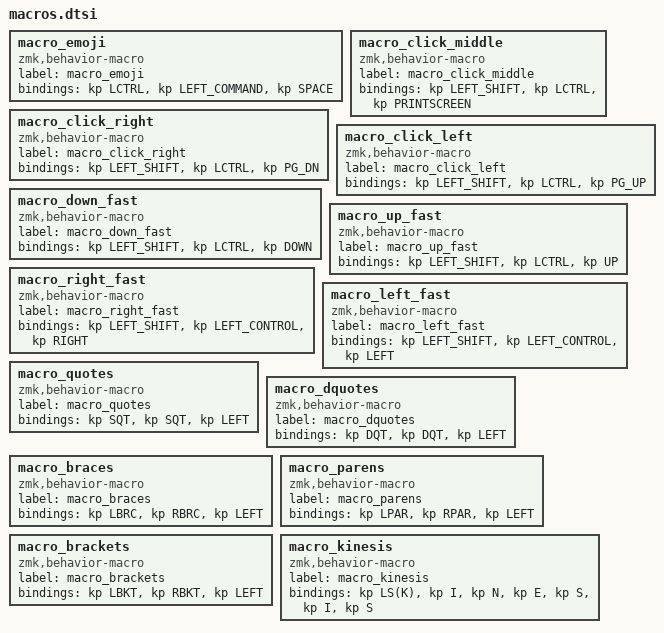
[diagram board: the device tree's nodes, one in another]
macro_emoji: macro_emoji{
compatible = "zmk,behavior-macro";
label = "macro_emoji";
#binding-cells = <0>;
bindings = <&kp LCTRL>, <&kp LEFT_COMMAND>, <&kp SPACE>;
};
macro_click_middle: macro_click_middle{
compatible = "zmk,behavior-macro";
label = "macro_click_middle";
#binding-cells = <0>;
bindings = <&kp LEFT_SHIFT>, <&kp LCTRL>, <&kp PRINTSCREEN>;
};
macro_click_right: macro_click_right{
compatible = "zmk,behavior-macro";
label = "macro_click_right";
#binding-cells = <0>;
bindings = <&kp LEFT_SHIFT>, <&kp LCTRL>, <&kp PG_DN>;
};
macro_click_left: macro_click_left{
compatible = "zmk,behavior-macro";
label = "macro_click_left";
#binding-cells = <0>;
bindings = <&kp LEFT_SHIFT>, <&kp LCTRL>, <&kp PG_UP>;
};
macro_down_fast: macro_down_fast{
compatible = "zmk,behavior-macro";
label = "macro_down_fast";
#binding-cells = <0>;
bindings = <&kp LEFT_SHIFT>, <&kp LCTRL>, <&kp DOWN>;
};
macro_up_fast: macro_up_fast{
compatible = "zmk,behavior-macro";
label = "macro_up_fast";
#binding-cells = <0>;
bindings = <&kp LEFT_SHIFT>, <&kp LCTRL>, <&kp UP>;
};
macro_right_fast: macro_right_fast{
compatible = "zmk,behavior-macro";
label = "macro_right_fast";
#binding-cells = <0>;
bindings = <&kp LEFT_SHIFT>, <&kp LEFT_CONTROL>, <&kp RIGHT>;
};
macro_left_fast: macro_left_fast{
compatible = "zmk,behavior-macro";
label = "macro_left_fast";
#binding-cells = <0>;
bindings = <&kp LEFT_SHIFT>, <&kp LEFT_CONTROL>, <&kp LEFT>;
};
macro_quotes: macro_quotes{
compatible = "zmk,behavior-macro";
label = "macro_quotes";
#binding-cells = <0>;
bindings = <&kp SQT>, <&kp SQT>, <&kp LEFT>;
};
macro_dquotes: macro_dquotes{
compatible = "zmk,behavior-macro";
label = "macro_dquotes";
#binding-cells = <0>;
bindings = <&kp DQT>, <&kp DQT>, <&kp LEFT>;
};
macro_braces: macro_braces{
compatible = "zmk,behavior-macro";
label = "macro_braces";
#binding-cells = <0>;
bindings = <&kp LBRC>, <&kp RBRC>, <&kp LEFT>;
};
macro_parens: macro_parens{
compatible = "zmk,behavior-macro";
label = "macro_parens";
#binding-cells = <0>;
bindings = <&kp LPAR>, <&kp RPAR>, <&kp LEFT>;
};
macro_brackets: macro_brackets{
compatible = "zmk,behavior-macro";
label = "macro_brackets";
#binding-cells = <0>;
bindings = <&kp LBKT>, <&kp RBKT>, <&kp LEFT>;
};
macro_kinesis: macro_kinesis{
compatible = "zmk,behavior-macro";
label = "macro_kinesis";
#binding-cells = <0>;
bindings = <&kp LS(K)>, <&kp I>, <&kp N>, <&kp E>, <&kp S>, <&kp I>, <&kp S>;
};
